AUTOSAR XML (schema 4-2-1)
standard types defined: uint8
package /DataTypes
  range DataConstr: phys 0..255
  base type My_uint8: category=Fixed_Value, base-type-size=8, base-type-encoding=NONE, native-declaration=unsigned char
package /DoorLockInterface
  sender receiver interface IO_SA1_SRI
    data DoorStatus: type=uint8
  sender receiver interface SA1_APP_SRI
    data DoorStatus: type=uint8
  sender receiver interface APP_SA2_SRI
    data LedStatus: type=uint8
  client server interface IO_SA2_Led_Switch
    operation Led_Switch: possible-error=[E_OK, E_Not_Ok]
      arg LedStatus: type=uint8, direction=IN
    error E_OK: error-code=0
    error E_Not_Ok: error-code=1
package /SWCs
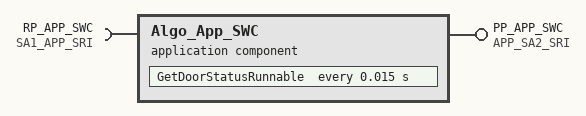
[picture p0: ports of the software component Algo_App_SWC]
  application sw component type Algo_App_SWC
    require port RP_APP_SWC: required-interface=SA1_APP_SRI
    provide port PP_APP_SWC: provided-interface=APP_SA2_SRI
    behavior APP_Beh
      timing event App_TimeEvent: start-on-event=GetDoorStatusRunnable, period=0.015
      runnable GetDoorStatusRunnable: symbol=GetDoorStatusFromSA1
        data-read-access:
          access DoorStatus: accessed-variable=RP_APP_SWC.DoorStatus
        data-write-access:
          access LedStatus: accessed-variable=PP_APP_SWC.LedStatus
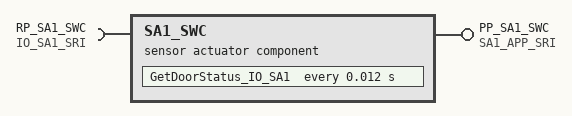
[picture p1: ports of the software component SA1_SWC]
  sensor actuator sw component type SA1_SWC
    provide port PP_SA1_SWC: provided-interface=SA1_APP_SRI
    require port RP_SA1_SWC: required-interface=IO_SA1_SRI
    behavior SA1_Beh
      timing event GetDoorStatus_Time: start-on-event=GetDoorStatus_IO_SA1, period=0.012
      runnable GetDoorStatus_IO_SA1: symbol=GetDoorStatusFromIO
        data-read-access:
          access DoorStatus_RP: accessed-variable=RP_SA1_SWC.DoorStatus
        data-write-access:
          access DoorStatus_PP: accessed-variable=PP_SA1_SWC.DoorStatus
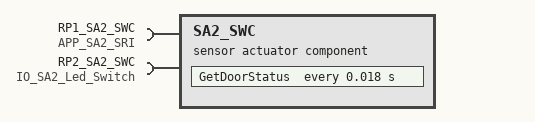
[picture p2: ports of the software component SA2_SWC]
  sensor actuator sw component type SA2_SWC
    require port RP1_SA2_SWC: required-interface=APP_SA2_SRI
    require port RP2_SA2_SWC: required-interface=IO_SA2_Led_Switch
    behavior SA2_Beh
      timing event GetDoorStatus_Time: start-on-event=GetDoorStatus, period=0.018
      runnable GetDoorStatus: symbol=GetDoorStatusFromApp
        data-read-access:
          access DoorStatus: accessed-variable=RP1_SA2_SWC.LedStatus
        sync call SYNC_SetLed: operation=RP2_SA2_SWC.Led_Switch
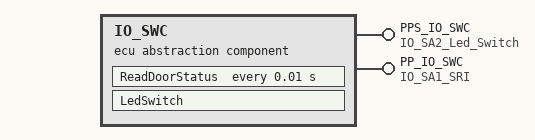
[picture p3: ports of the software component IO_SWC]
  ecu abstraction sw component type IO_SWC
    provide port PPS_IO_SWC: provided-interface=IO_SA2_Led_Switch
    provide port PP_IO_SWC: provided-interface=IO_SA1_SRI
    behavior IO_Beh
      timing event ReadDoorStatus_Time: start-on-event=ReadDoorStatus, period=0.01
      operation invoked event InvokedEvent: start-on-event=LedSwitch, operation=PPS_IO_SWC.Led_Switch
      runnable ReadDoorStatus: symbol=SendDoorStatuToSA1
        data-write-access:
          access DoorStatus_PP: accessed-variable=PP_IO_SWC.DoorStatus
      runnable LedSwitch
package /Composition
  composition sw component type RootCompisite
    4 x component:
      AppSWC_Comp: type=Algo_App_SWC
      SA1_SWC_Comp: type=SA1_SWC
      SA2_SWC_Comp: type=SA2_SWC
      IO_SWC_Comp: type=IO_SWC
    connect IO_SWC_Comp.PP_IO_SWC -> SA1_SWC_Comp.RP_SA1_SWC
    connect SA1_SWC_Comp.PP_SA1_SWC -> AppSWC_Comp.RP_APP_SWC
    connect AppSWC_Comp.PP_APP_SWC -> SA2_SWC_Comp.RP1_SA2_SWC
    connect IO_SWC_Comp.PPS_IO_SWC -> SA2_SWC_Comp.RP2_SA2_SWC
